# NSS_0_CFG_EMAC register map
Vendor: Texas Instruments
Peripheral module from a debugger description file (folder 66AK2G0x_66AK2G1x).
Registers are 32-bit, read-only, reset 0x0 unless marked. A register's access mark holds for its fields unless they carry their own. Offsets are as the file gives them; lines under a group give offsets from that group; [hi:lo] are bit positions; {n}, {i} and the like mark numbered series; 'fields as' and 'values as' point back to an identical list; <NAME> marks a mode.

## NSS_0_CFG_EMAC
0x00 SS_IDVER reset 0x4EE71100
  [31:0] REV — TI internal data. Identifies revision of peripheral.
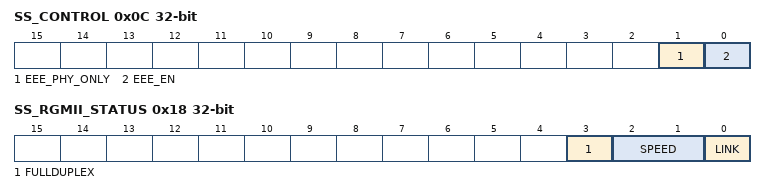
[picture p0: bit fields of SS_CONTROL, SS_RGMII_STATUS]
0x0C SS_CONTROL access per field
  [1] EEE_PHY_ONLY rw — Energy Efficient Enable Phy Only Mode:
  [0] EEE_EN rw — Energy Efficient Ethernet Enable:
0x18 SS_RGMII_STATUS
  [3] FULLDUPLEX — Rgmii full dulex:
  [2:1] SPEED — Rgmii speed:
  [0] LINK — Rgmii link indicator:
0x1C SS_SUBSSYSTEM_STATUS
  [0] EEE_CLKSTOP_ACK — Energy Efficient Ethernet clockstop acknowledge from CPSW_2U
